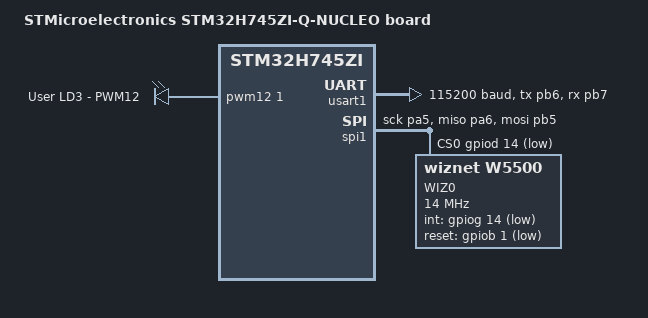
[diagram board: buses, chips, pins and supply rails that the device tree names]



/ {
	model = "STMicroelectronics STM32H745ZI-Q-NUCLEO board";
	compatible = "st,stm32h745zi-q-nucleo";

	/* HW resources belonging to CM7 */
	chosen {
		zephyr,console = &usart1;
		zephyr,shell-uart = &usart1;
		zephyr,dtcm = &dtcm;
		zephyr,sram = &sram0;
		zephyr,flash = &flash0;
	};

	pwmleds {
		compatible = "pwm-leds";

		red_pwm_led: red_pwm_led {
			pwms = <&pwm12 1 4 PWM_POLARITY_NORMAL>;
			label = "User LD3 - PWM12";
		};
	};

	aliases {
		led0 = &green_led;
		pwm-led0 = &red_pwm_led;
		sw0 = &user_button;
	};
};

&mac {
	status = "disabled";
};

&usart1 {
	pinctrl-0 = <&usart1_tx_pb6 &usart1_rx_pb7>;
	current-speed = <115200>;
	status = "okay";
};


&spi1 {
	status = "okay";

	pinctrl-0 = <&spi1_sck_pa5 &spi1_miso_pa6 &spi1_mosi_pb5>;
	cs-gpios = <&gpiod 14 (GPIO_ACTIVE_LOW | GPIO_PULL_UP)>;
	
	enc424j600@0 {
		status = "disabled";
		compatible = "microchip,enc424j600";
		reg = <0>;
		spi-max-frequency = <20000000>;
		int-gpios = <&arduino_header 3 GPIO_ACTIVE_LOW>;	/* PIO1_28 => PLU_IN3  */
		label = "ETH_0";
	};

	wizenet@0 {
		status = "okay";
		compatible = "wiznet,w5500";
		reg = <0>;
		spi-max-frequency = <14000000>;
		int-gpios = <&gpiog 14 GPIO_ACTIVE_LOW>;	/* PIO1_28 => PLU_IN3  */
		reset-gpios = <&gpiob 1 GPIO_ACTIVE_LOW>;	/* PIO1_28 => PLU_IN3  */
		label = "WIZ0";
	};
};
